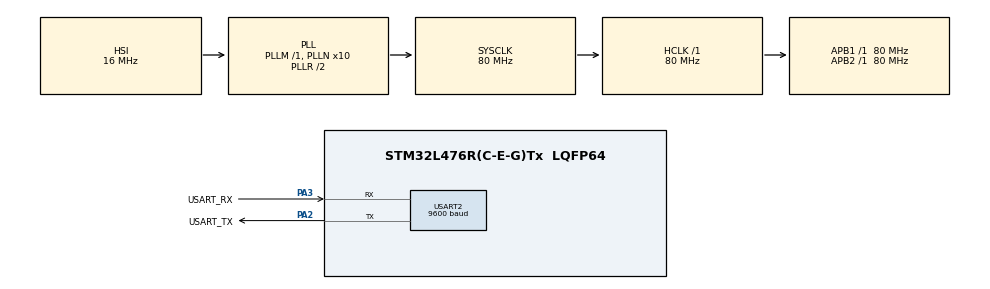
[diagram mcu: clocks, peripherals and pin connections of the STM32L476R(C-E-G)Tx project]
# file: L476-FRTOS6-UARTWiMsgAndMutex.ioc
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FREERTOS.Mutexes01=myMutex01,Dynamic,NULL,Available
FREERTOS.Queues01=myQueue01,16,MSGQUEUE_OBJ_t,0,Dynamic,NULL,NULL
FREERTOS.Tasks01=myTask01,24,128,StartTask01,Default,NULL,Dynamic,NULL,NULL;myTask02,24,128,StartTask02,Default,NULL,Dynamic,NULL,NULL;myTask03,24,128,StartTask03,Default,NULL,Dynamic,NULL,NULL
FREERTOS.configUSE_NEWLIB_REENTRANT=1
Mcu.Family=STM32L4
Mcu.Name=STM32L476R(C-E-G)Tx
Mcu.Package=LQFP64
NVIC.PriorityGroup=NVIC_PRIORITYGROUP_4
NVIC.TIM7_IRQn=true\:15\:0\:false\:false\:true\:false\:false\:true\:true
NVIC.TimeBase=TIM7_IRQn
NVIC.TimeBaseIP=TIM7
PA2.GPIO_Label=USART_TX
PA2.GPIO_Mode=GPIO_MODE_AF_PP
PA2.GPIO_PuPd=GPIO_NOPULL
PA2.GPIO_Speed=GPIO_SPEED_FREQ_VERY_HIGH
PA2.Mode=Asynchronous
PA2.Signal=USART2_TX
PA3.GPIO_Label=USART_RX
PA3.GPIO_Mode=GPIO_MODE_AF_PP
PA3.GPIO_PuPd=GPIO_NOPULL
PA3.GPIO_Speed=GPIO_SPEED_FREQ_VERY_HIGH
PA3.Mode=Asynchronous
PA3.Signal=USART2_RX
ProjectManager.HeapSize=0x200
ProjectManager.StackSize=0x400
ProjectManager.TargetToolchain=STM32CubeIDE
RCC.ADCFreq_Value=64000000
RCC.AHBFreq_Value=80000000
RCC.APB1Freq_Value=80000000
RCC.APB1TimFreq_Value=80000000
RCC.APB2Freq_Value=80000000
RCC.APB2TimFreq_Value=80000000
RCC.CortexFreq_Value=80000000
RCC.HCLKFreq_Value=80000000
RCC.HSE_VALUE=8000000
RCC.HSI_VALUE=16000000
RCC.MSI_VALUE=4000000
RCC.PLLN=10
RCC.PLLSourceVirtual=RCC_PLLSOURCE_HSI
RCC.PREFETCH_ENABLE=1
RCC.SYSCLKFreq_VALUE=80000000
RCC.SYSCLKSource=RCC_SYSCLKSOURCE_PLLCLK
RCC.USBFreq_Value=64000000
RCC.VCOOutputFreq_Value=160000000
USART2.BaudRate=9600
USART2.VirtualMode-Asynchronous=VM_ASYNC
VP_FREERTOS_VS_CMSIS_V2.Mode=CMSIS_V2
VP_SYS_VS_tim7.Mode=TIM7
board=NUCLEO-L476RG

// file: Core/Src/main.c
/* USER CODE BEGIN Header */
/**
  ******************************************************************************
  * @file           : main.c
  * @brief          : Main program body
  ******************************************************************************
  * @attention
  *
  * Copyright (c) 2026 STMicroelectronics.
  * All rights reserved.
  *
  * This software is licensed under terms that can be found in the LICENSE file
  * in the root directory of this software component.
  * If no LICENSE file comes with this software, it is provided AS-IS.
  *
  ******************************************************************************
  */
/* USER CODE END Header */
#include "main.h"
#include "cmsis_os.h"

/* USER CODE BEGIN Includes */
#include "stdio.h"
#include "string.h"
/* USER CODE END Includes */

/* USER CODE BEGIN PTD */
typedef struct{
	char buf[32];
	uint32_t tick;
} MSGQUEUE_OBJ_t;
/* USER CODE END PTD */

UART_HandleTypeDef huart2;

/* Definitions for myTask01 */
osThreadId_t myTask01Handle;
const osThreadAttr_t myTask01_attributes = {
  .name = "myTask01",
  .stack_size = 128 * 4,
  .priority = (osPriority_t) osPriorityNormal,
};
/* Definitions for myTask02 */
osThreadId_t myTask02Handle;
const osThreadAttr_t myTask02_attributes = {
  .name = "myTask02",
  .stack_size = 128 * 4,
  .priority = (osPriority_t) osPriorityNormal,
};
/* Definitions for myTask03 */
osThreadId_t myTask03Handle;
const osThreadAttr_t myTask03_attributes = {
  .name = "myTask03",
  .stack_size = 128 * 4,
  .priority = (osPriority_t) osPriorityNormal,
};
/* Definitions for myQueue01 */
osMessageQueueId_t myQueue01Handle;
const osMessageQueueAttr_t myQueue01_attributes = {
  .name = "myQueue01"
};
/* Definitions for myMutex01 */
osMutexId_t myMutex01Handle;
const osMutexAttr_t myMutex01_attributes = {
  .name = "myMutex01"
};

void SystemClock_Config(void);
static void MX_GPIO_Init(void);
static void MX_USART2_UART_Init(void);
void StartTask01(void *argument);
void StartTask02(void *argument);
void StartTask03(void *argument);

/* USER CODE BEGIN 0 */
int __io_putchar(int ch){
	HAL_UART_Transmit(&huart2, (uint8_t *)&ch, 1, HAL_MAX_DELAY);
	return ch;
}
/* USER CODE END 0 */

int main(void)
{

  /* MCU Configuration--------------------------------------------------------*/

  /* Reset of all peripherals, Initializes the Flash interface and the Systick. */
  HAL_Init();

  /* Configure the system clock */
  SystemClock_Config();

  /* Initialize all configured peripherals */
  MX_GPIO_Init();
  MX_USART2_UART_Init();

  /* Init scheduler */
  osKernelInitialize();
  /* Create the mutex(es) */
  /* creation of myMutex01 */
  myMutex01Handle = osMutexNew(&myMutex01_attributes);

  /* Create the queue(s) */
  /* creation of myQueue01 */
  myQueue01Handle = osMessageQueueNew (16, sizeof(MSGQUEUE_OBJ_t), &myQueue01_attributes);

  /* Create the thread(s) */
  /* creation of myTask01 */
  myTask01Handle = osThreadNew(StartTask01, NULL, &myTask01_attributes);

  /* creation of myTask02 */
  myTask02Handle = osThreadNew(StartTask02, NULL, &myTask02_attributes);

  /* creation of myTask03 */
  myTask03Handle = osThreadNew(StartTask03, NULL, &myTask03_attributes);

  /* Start scheduler */
  osKernelStart();

  /* We should never get here as control is now taken by the scheduler */

  /* Infinite loop */
  while (1)
  {

  }
}

void SystemClock_Config(void)
{
  RCC_OscInitTypeDef RCC_OscInitStruct = {0};
  RCC_ClkInitTypeDef RCC_ClkInitStruct = {0};

  /** Configure the main internal regulator output voltage
  */
  if (HAL_PWREx_ControlVoltageScaling(PWR_REGULATOR_VOLTAGE_SCALE1) != HAL_OK)
  {
    Error_Handler();
  }

  /** Initializes the RCC Oscillators according to the specified parameters
  * in the RCC_OscInitTypeDef structure.
  */
  RCC_OscInitStruct.OscillatorType = RCC_OSCILLATORTYPE_HSI;
  RCC_OscInitStruct.HSIState = RCC_HSI_ON;
  RCC_OscInitStruct.HSICalibrationValue = RCC_HSICALIBRATION_DEFAULT;
  RCC_OscInitStruct.PLL.PLLState = RCC_PLL_ON;
  RCC_OscInitStruct.PLL.PLLSource = RCC_PLLSOURCE_HSI;
  RCC_OscInitStruct.PLL.PLLM = 1;
  RCC_OscInitStruct.PLL.PLLN = 10;
  RCC_OscInitStruct.PLL.PLLP = RCC_PLLP_DIV7;
  RCC_OscInitStruct.PLL.PLLQ = RCC_PLLQ_DIV2;
  RCC_OscInitStruct.PLL.PLLR = RCC_PLLR_DIV2;
  if (HAL_RCC_OscConfig(&RCC_OscInitStruct) != HAL_OK)
  {
    Error_Handler();
  }

  /** Initializes the CPU, AHB and APB buses clocks
  */
  RCC_ClkInitStruct.ClockType = RCC_CLOCKTYPE_HCLK|RCC_CLOCKTYPE_SYSCLK
                              |RCC_CLOCKTYPE_PCLK1|RCC_CLOCKTYPE_PCLK2;
  RCC_ClkInitStruct.SYSCLKSource = RCC_SYSCLKSOURCE_PLLCLK;
  RCC_ClkInitStruct.AHBCLKDivider = RCC_SYSCLK_DIV1;
  RCC_ClkInitStruct.APB1CLKDivider = RCC_HCLK_DIV1;
  RCC_ClkInitStruct.APB2CLKDivider = RCC_HCLK_DIV1;

  if (HAL_RCC_ClockConfig(&RCC_ClkInitStruct, FLASH_LATENCY_4) != HAL_OK)
  {
    Error_Handler();
  }
}

static void MX_USART2_UART_Init(void)
{

  huart2.Instance = USART2;
  huart2.Init.BaudRate = 9600;
  huart2.Init.WordLength = UART_WORDLENGTH_8B;
  huart2.Init.StopBits = UART_STOPBITS_1;
  huart2.Init.Parity = UART_PARITY_NONE;
  huart2.Init.Mode = UART_MODE_TX_RX;
  huart2.Init.HwFlowCtl = UART_HWCONTROL_NONE;
  huart2.Init.OverSampling = UART_OVERSAMPLING_16;
  huart2.Init.OneBitSampling = UART_ONE_BIT_SAMPLE_DISABLE;
  huart2.AdvancedInit.AdvFeatureInit = UART_ADVFEATURE_NO_INIT;
  if (HAL_UART_Init(&huart2) != HAL_OK)
  {
    Error_Handler();
  }

}

static void MX_GPIO_Init(void)
{

  /* GPIO Ports Clock Enable */
  __HAL_RCC_GPIOA_CLK_ENABLE();

}

void StartTask01(void *argument)
{
  /* USER CODE BEGIN 5 */
	MSGQUEUE_OBJ_t msg;
	strcpy(msg.buf, "Task 1 ");
  /* Infinite loop */
  for(;;)
  {
	  osMutexAcquire(myMutex01Handle, osWaitForever);
	  msg.tick=osKernelGetTickCount();
	  osMessageQueuePut(myQueue01Handle, &msg, 0U, 0U);
	  osMutexRelease(myMutex01Handle);

	  osDelay(3000);
  }
  /* USER CODE END 5 */
}

void StartTask02(void *argument)
{
  /* USER CODE BEGIN StartTask02 */
	MSGQUEUE_OBJ_t msg;
	strcpy(msg.buf, "Task  2");
  /* Infinite loop */
  for(;;)
  {
	  osMutexAcquire(myMutex01Handle, osWaitForever);
	  msg.tick=osKernelGetTickCount();
	  osMessageQueuePut(myQueue01Handle, &msg, 0U, 0U);
	  osMutexRelease(myMutex01Handle);

	  osDelay(5000);
  }
  /* USER CODE END StartTask02 */
}

void StartTask03(void *argument)
{
  /* USER CODE BEGIN StartTask03 */
	MSGQUEUE_OBJ_t msg;
	osStatus_t status;
  /* Infinite loop */
  for(;;)
  {
	  status = osMessageQueueGet(myQueue01Handle, &msg, NULL, 0U); // wait for message

	  if(status==osOK){
		  printf("%s @ %5ld tick \r\n", msg.buf, msg.tick);

		  osThreadYield();
	  }
  }
  /* USER CODE END StartTask03 */
}

void HAL_TIM_PeriodElapsedCallback(TIM_HandleTypeDef *htim)
{
  if (htim->Instance == TIM7)
  {
    HAL_IncTick();
  }
}

void Error_Handler(void)
{
  __disable_irq();
  while (1)
  {
  }
}
